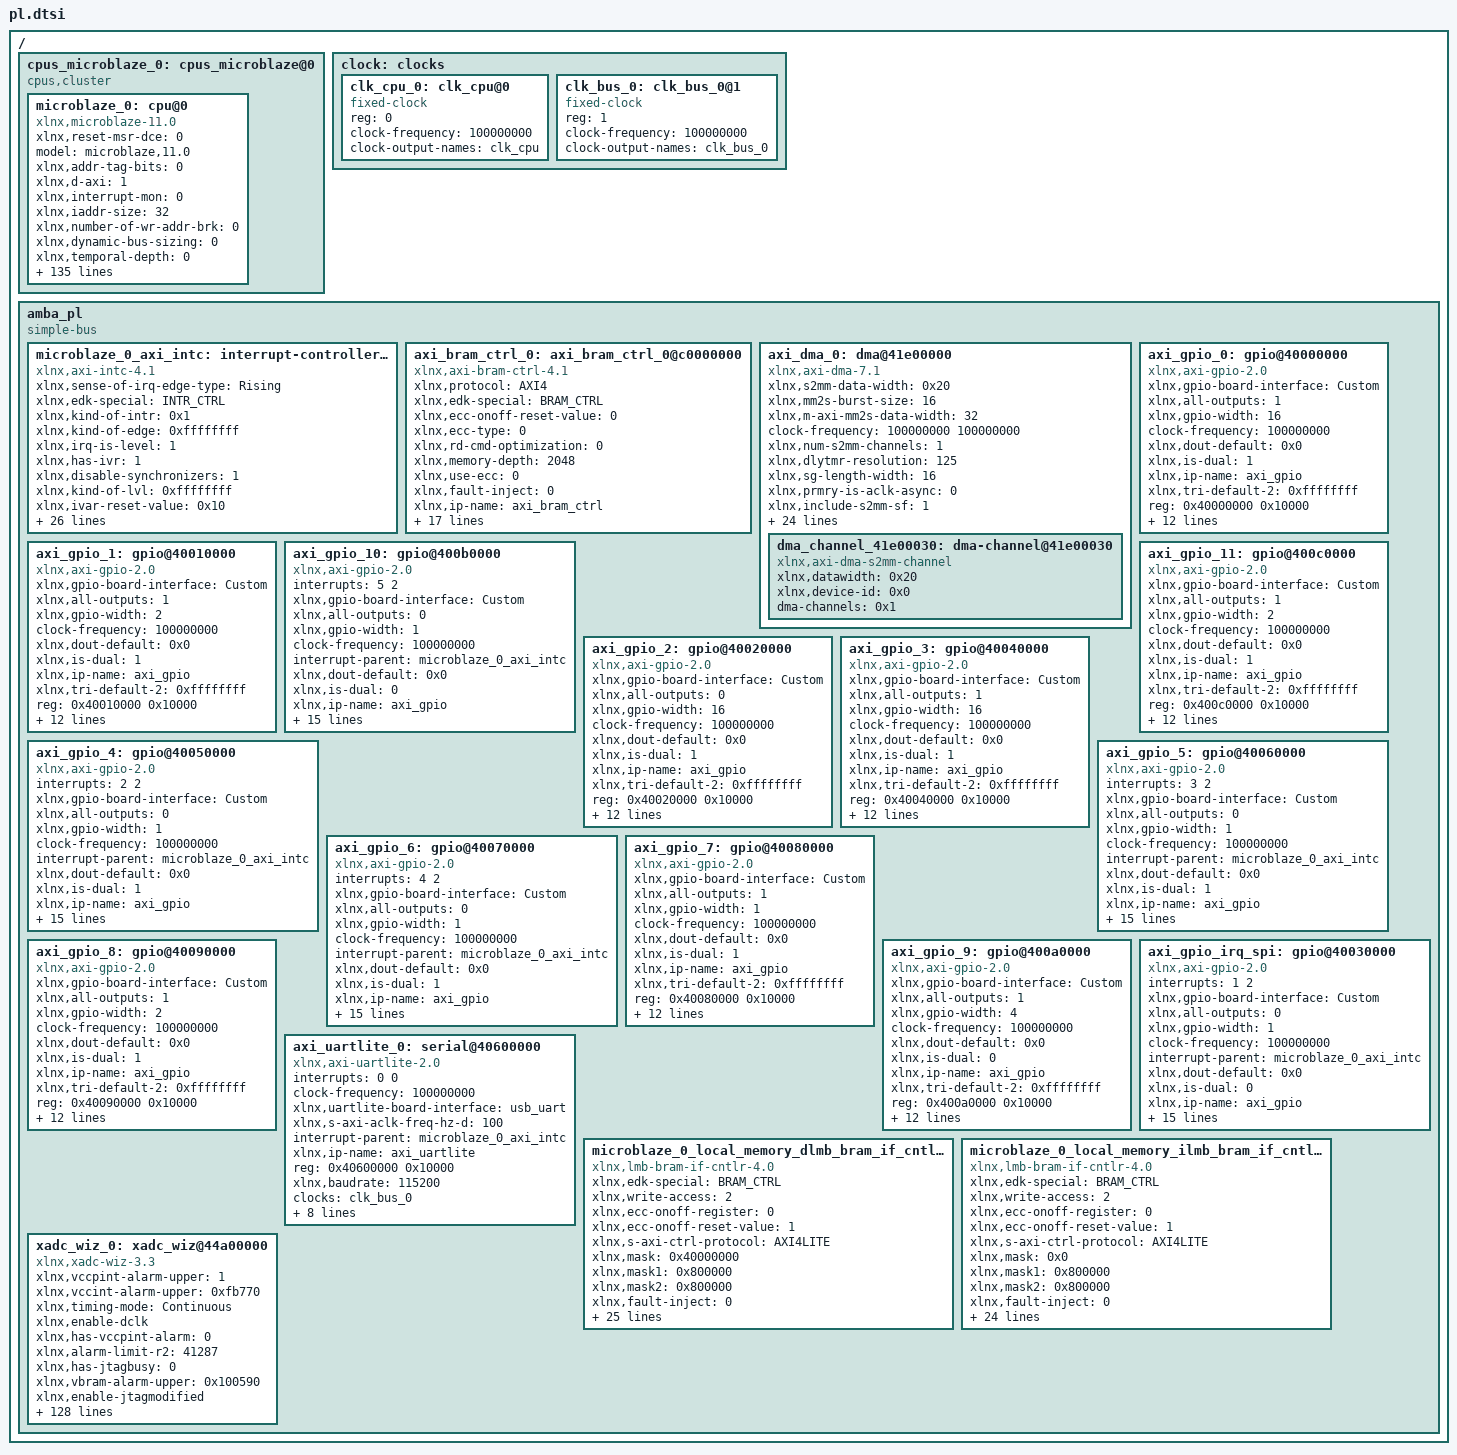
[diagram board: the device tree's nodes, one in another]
/ {
	cpus_microblaze_0: cpus_microblaze@0 {
		#cpu-mask-cells = <1>;
		compatible = "cpus,cluster";
		#address-cells = <1>;
		#size-cells = <0>;
		microblaze_0: cpu@0 {
			xlnx,reset-msr-dce = <0>;
			model = "microblaze,11.0";
			xlnx,addr-tag-bits = <0>;
			xlnx,d-axi = <1>;
			xlnx,interrupt-mon = <0>;
			xlnx,iaddr-size = <32>;
			xlnx,number-of-wr-addr-brk = <0>;
			xlnx,dynamic-bus-sizing = <0>;
			xlnx,temporal-depth = <0>;
			xlnx,use-interrupt = <2>;
			xlnx,optimization = <0>;
			xlnx,ip-axi-mon = <0>;
			xlnx,ip-name = "microblaze";
			d-cache-highaddr = <0x3fffffff>;
			xlnx,dcache-force-tag-lutram = <0>;
			xlnx,pc-width = <32>;
			xlnx,interrupt-is-edge = <0>;
			reg = <0x0>;
			xlnx,async-interrupt = <1>;
			xlnx,use-mmu = <0>;
			xlnx,reset-msr-ee = <0>;
			xlnx,icache-victims = <0>;
			xlnx,use-reorder-instr = <1>;
			xlnx,d-lmb-mon = <0>;
			xlnx,d-lmb-protocol = <0>;
			xlnx,ill-opcode-exception = <0>;
			xlnx,dcache-always-used = <1>;
			xlnx,use-div = <0>;
			xlnx,dc-axi-mon = <0>;
			xlnx,debug-trace-async-reset = <0>;
			xlnx,trace = <0>;
			xlnx,part = "xc7a35tcpg236-1";
			i-cache-baseaddr = <0x0>;
			xlnx,use-config-reset = <0>;
			xlnx,pvr = <0>;
			xlnx,i-lmb-mon = <0>;
			xlnx,dcache-byte-size = <8192>;
			xlnx,fault-tolerant = <0>;
			xlnx,family = "artix7";
			compatible = "xlnx,microblaze-11.0" , "xlnx,microblaze";
			xlnx,data-size = <32>;
			xlnx,mmu-zones = <16>;
			xlnx,debug-trace-size = <8192>;
			xlnx,mmu-privileged-instr = <0>;
			xlnx,enable-discrete-ports = <0>;
			d-cache-line-size = <16>;
			xlnx,d-lmb = <1>;
			xlnx,sco = <0>;
			xlnx,reset-msr-eip = <0>;
			xlnx,debug-interface = <0>;
			clock-frequency = <100000000>;
			xlnx,use-ext-brk = <0>;
			xlnx,daddr-size = <32>;
			xlnx,debug-enabled = <1>;
			xlnx,reset-msr-ice = <0>;
			xlnx,num-sync-ff-dbg-trace-clk = <2>;
			xlnx,i-lmb-protocol = <0>;
			xlnx,endianness = <1>;
			xlnx,fsl-exception = <0>;
			i-cache-line-size = <16>;
			xlnx,use-extended-fsl-instr = <0>;
			xlnx,reset-msr = <0x0>;
			xlnx,dp-axi-mon = <0>;
			device_type = "cpu";
			xlnx,branch-target-cache-size = <0>;
			xlnx,dcache-use-writeback = <0>;
			xlnx,div-zero-exception = <0>;
			xlnx,mmu-tlb-access = <3>;
			bus-handle = <&amba_pl>;
			xlnx,cache-byte-size = <8192>;
			xlnx,pvr-user2 = <0x0>;
			xlnx,opcode-0x0-illegal = <0>;
			xlnx,icache-line-len = <4>;
			xlnx,ecc-use-ce-exception = <0>;
			xlnx,base-vectors = <0x0>;
			xlnx,edk-special = "microblaze";
			xlnx,use-dcache = <0>;
			xlnx,use-barrel = <0>;
			xlnx,reset-msr-bip = <0>;
			xlnx,allow-dcache-wr = <1>;
			xlnx,debug-external-trace = <0>;
			xlnx,addr-size = <32>;
			xlnx,piaddr-size = <32>;
			i-cache-highaddr = <0x3fffffff>;
			xlnx,num-sync-ff-clk-debug = <2>;
			xlnx,debug-event-counters = <5>;
			xlnx,fpu-exception = <0>;
			xlnx,allow-icache-wr = <1>;
			xlnx,g-use-exceptions = <0>;
			xlnx,i-axi = <0>;
			xlnx,g-template-list = <0>;
			xlnx,icache-streams = <0>;
			xlnx,dcache-line-len = <4>;
			xlnx,num-sync-ff-clk = <2>;
			xlnx,edk-iptype = "PROCESSOR";
			xlnx,use-stack-protection = <0>;
			xlnx,use-hw-mul = <0>;
			xlnx,num-sync-ff-dbg-clk = <1>;
			xlnx,interconnect = <2>;
			xlnx,debug-latency-counters = <1>;
			i-cache-size = <8192>;
			xlnx,exceptions-in-delay-slots = <1>;
			xlnx,use-fpu = <0>;
			xlnx,reset-msr-ie = <0>;
			xlnx,edge-is-positive = <1>;
			xlnx,use-pcmp-instr = <0>;
			xlnx,use-icache = <0>;
			d-cache-size = <8192>;
			xlnx,memory-ip-list = "microblaze_0_local_memory_ilmb_bram_if_cntlr_memory" , "microblaze_0_local_memory_dlmb_bram_if_cntlr_memory";
			xlnx,async-wakeup = <3>;
			xlnx,use-non-secure = <0>;
			xlnx,dcache-addr-tag = <0>;
			xlnx,number-of-rd-addr-brk = <0>;
			d-cache-baseaddr = <0x0>;
			xlnx,area-optimized = <0>;
			xlnx,avoid-primitives = <0>;
			xlnx,lockstep-slave = <0>;
			xlnx,use-ext-nm-brk = <0>;
			xlnx,instr-size = <32>;
			interrupt-handle = <&microblaze_0_axi_intc>;
			xlnx,icache-always-used = <1>;
			xlnx,i-lmb = <1>;
			xlnx,mmu-dtlb-size = <4>;
			xlnx,lockstep-select = <0>;
			xlnx,lmb-data-size = <32>;
			xlnx,ic-axi-mon = <0>;
			xlnx,enable-conversion = <0>;
			xlnx,num-sync-ff-clk-irq = <1>;
			xlnx,fsl-links = <0>;
			timebase-frequency = <100000000>;
			xlnx,icache-force-tag-lutram = <0>;
			xlnx,dcache-data-width = <0>;
			xlnx,dcache-victims = <0>;
			xlnx,use-branch-target-cache = <0>;
			xlnx,debug-profile-size = <0>;
			xlnx,unaligned-exceptions = <0>;
			xlnx,lockstep-master = <0>;
			xlnx,freq = <100000000>;
			xlnx,number-of-pc-brk = <1>;
			xlnx,mmu-itlb-size = <2>;
			xlnx,imprecise-exceptions = <0>;
			xlnx,use-msr-instr = <0>;
			xlnx,icache-data-width = <0>;
			xlnx,debug-counter-width = <32>;
		};
	};
	clock: clocks {
		#address-cells = <1>;
		#size-cells = <0>;
		clk_cpu_0: clk_cpu@0 {
			compatible = "fixed-clock";
			reg = <0>;
			clock-frequency = <100000000>;
			clock-output-names = "clk_cpu";
			#clock-cells = <0>;
		};
		clk_bus_0: clk_bus_0@1 {
			compatible = "fixed-clock";
			reg = <1>;
			clock-frequency = <100000000>;
			clock-output-names = "clk_bus_0";
			#clock-cells = <0>;
		};
	};
	amba_pl: amba_pl {
		ranges;
		compatible = "simple-bus";
		#address-cells = <1>;
		#size-cells = <1>;
		microblaze_0_axi_intc: interrupt-controller@41200000 {
			#interrupt-cells = <2>;
			xlnx,sense-of-irq-edge-type = "Rising";
			xlnx,edk-special = "INTR_CTRL";
			xlnx,kind-of-intr = <0x1>;
			xlnx,kind-of-edge = <0xffffffff>;
			xlnx,irq-is-level = <1>;
			xlnx,has-ivr = <1>;
			compatible = "xlnx,axi-intc-4.1" , "xlnx,xps-intc-1.00.a";
			xlnx,disable-synchronizers = <1>;
			xlnx,kind-of-lvl = <0xffffffff>;
			xlnx,ivar-reset-value = <0x10>;
			xlnx,irq-active = <0x1>;
			xlnx,en-cascade-mode = <0>;
			xlnx,ip-name = "axi_intc";
			xlnx,has-ilr = <0>;
			reg = <0x41200000 0x10000>;
			xlnx,addr-width = <0x20>;
			xlnx,s-axi-aclk-freq-mhz = <100>;
			xlnx,num-sw-intr = <0>;
			xlnx,irq-connection = <0>;
			xlnx,num-intr-inputs = <0x6>;
			xlnx,has-sie = <1>;
			xlnx,enable-async = <0>;
			xlnx,has-cie = <1>;
			xlnx,num-sync-ff = <2>;
			xlnx,edk-iptype = "PERIPHERAL";
			xlnx,mb-clk-not-connected = <1>;
			xlnx,has-ipr = <1>;
			xlnx,sense-of-irq-level-type = "Active_High";
			xlnx,cascade-master = <0>;
			xlnx,processor-clk-freq-mhz = <100>;
			status = "okay";
			xlnx,is-fast = <0x1>;
			xlnx,has-fast = <1>;
			xlnx,ivar-rst-val = <0x10>;
			interrupt-controller;
			xlnx,async-intr = <0xffffffc0>;
			xlnx,name = "microblaze_0_axi_intc";
		};
		axi_bram_ctrl_0: axi_bram_ctrl_0@c0000000 {
			xlnx,protocol = "AXI4";
			xlnx,edk-special = "BRAM_CTRL";
			compatible = "xlnx,axi-bram-ctrl-4.1" , "xlnx,axi-bram-ctrl";
			xlnx,ecc-onoff-reset-value = <0>;
			xlnx,ecc-type = <0>;
			xlnx,rd-cmd-optimization = <0>;
			xlnx,memory-depth = <2048>;
			xlnx,use-ecc = <0>;
			xlnx,fault-inject = <0>;
			xlnx,ip-name = "axi_bram_ctrl";
			reg = <0xc0000000 0x2000>;
			xlnx,bmg-instance = "EXTERNAL";
			xlnx,s-axi-ctrl-addr-width = <32>;
			xlnx,read-latency = <1>;
			xlnx,id-width = <0>;
			xlnx,s-axi-supports-narrow-burst = <0>;
			xlnx,supports-narrow-burst = <0>;
			xlnx,single-port-bram = <0>;
			xlnx,ecc = <0>;
			xlnx,edk-iptype = "PERIPHERAL";
			status = "okay";
			xlnx,data-width = <32>;
			xlnx,bram-addr-width = <11>;
			xlnx,bram-inst-mode = "EXTERNAL";
			xlnx,s-axi-ctrl-data-width = <32>;
			xlnx,mem-depth = <2048>;
			xlnx,s-axi-id-width = <1>;
			xlnx,name = "axi_bram_ctrl_0";
		};
		axi_dma_0: dma@41e00000 {
			compatible = "xlnx,axi-dma-7.1" , "xlnx,axi-dma-1.00.a";
			xlnx,s2mm-data-width = <0x20>;
			xlnx,mm2s-burst-size = <16>;
			xlnx,m-axi-mm2s-data-width = <32>;
			clock-frequency = <100000000 100000000>;
			xlnx,num-s2mm-channels = <1>;
			xlnx,dlytmr-resolution = <125>;
			xlnx,sg-length-width = <16>;
			xlnx,prmry-is-aclk-async = <0>;
			xlnx,include-s2mm-sf = <1>;
			#dma-cells = <1>;
			xlnx,ip-name = "axi_dma";
			xlnx,single-interface = <0>;
			xlnx,sg-include-stscntrl-strm = <0>;
			xlnx,include-s2mm-dre = <0>;
			reg = <0x41e00000 0x10000>;
			xlnx,addr-width = <32>;
			xlnx,include-s2mm = <1>;
			clocks = <&clk_bus_0 &clk_bus_0>;
			xlnx,s-axis-s2mm-tdata-width = <32>;
			xlnx,micro-dma = <0>;
			xlnx,increase-throughput = <0>;
			xlnx,mm2s-data-width = <0x20>;
			xlnx,addrwidth = <0x20>;
			xlnx,sg-use-stsapp-length = <0>;
			xlnx,m-axis-mm2s-tdata-width = <32>;
			xlnx,edk-iptype = "PERIPHERAL";
			xlnx,s2mm-burst-size = <16>;
			xlnx,m-axi-s2mm-data-width = <32>;
			xlnx,num-mm2s-channels = <1>;
			xlnx,enable-multi-channel = <0>;
			status = "okay";
			xlnx,include-mm2s-sf = <1>;
			clock-names = "s_axi_lite_aclk" , "m_axi_sg_aclk" , "m_axi_s2mm_aclk";
			xlnx,include-mm2s = <0>;
			xlnx,include-mm2s-dre = <0>;
			xlnx,name = "axi_dma_0";
			dma_channel_41e00030: dma-channel@41e00030 {
				xlnx,datawidth = <0x20>;
				xlnx,device-id = <0x0>;
				compatible = "xlnx,axi-dma-s2mm-channel";
				dma-channels = <0x1>;
			};
		};
		axi_gpio_0: gpio@40000000 {
			xlnx,gpio-board-interface = "Custom";
			compatible = "xlnx,axi-gpio-2.0" , "xlnx,xps-gpio-1.00.a";
			xlnx,all-outputs = <1>;
			#gpio-cells = <2>;
			xlnx,gpio-width = <16>;
			clock-frequency = <100000000>;
			xlnx,dout-default = <0x0>;
			xlnx,is-dual = <1>;
			xlnx,ip-name = "axi_gpio";
			xlnx,tri-default-2 = <0xffffffff>;
			reg = <0x40000000 0x10000>;
			xlnx,all-inputs-2 = <0>;
			clocks = <&clk_bus_0>;
			xlnx,all-outputs-2 = <1>;
			gpio-controller;
			xlnx,interrupt-present = <0>;
			xlnx,gpio2-board-interface = "Custom";
			xlnx,edk-iptype = "PERIPHERAL";
			xlnx,dout-default-2 = <0x0>;
			status = "okay";
			xlnx,gpio2-width = <16>;
			clock-names = "s_axi_aclk";
			xlnx,tri-default = <0xffffffff>;
			xlnx,name = "axi_gpio_0";
			xlnx,all-inputs = <0>;
		};
		axi_gpio_1: gpio@40010000 {
			xlnx,gpio-board-interface = "Custom";
			compatible = "xlnx,axi-gpio-2.0" , "xlnx,xps-gpio-1.00.a";
			xlnx,all-outputs = <1>;
			#gpio-cells = <2>;
			xlnx,gpio-width = <2>;
			clock-frequency = <100000000>;
			xlnx,dout-default = <0x0>;
			xlnx,is-dual = <1>;
			xlnx,ip-name = "axi_gpio";
			xlnx,tri-default-2 = <0xffffffff>;
			reg = <0x40010000 0x10000>;
			xlnx,all-inputs-2 = <0>;
			clocks = <&clk_bus_0>;
			xlnx,all-outputs-2 = <1>;
			gpio-controller;
			xlnx,interrupt-present = <0>;
			xlnx,gpio2-board-interface = "Custom";
			xlnx,edk-iptype = "PERIPHERAL";
			xlnx,dout-default-2 = <0x0>;
			status = "okay";
			xlnx,gpio2-width = <2>;
			clock-names = "s_axi_aclk";
			xlnx,tri-default = <0xffffffff>;
			xlnx,name = "axi_gpio_1";
			xlnx,all-inputs = <0>;
		};
		axi_gpio_10: gpio@400b0000 {
			#interrupt-cells = <2>;
			interrupts = < 5 2 >;
			xlnx,gpio-board-interface = "Custom";
			compatible = "xlnx,axi-gpio-2.0" , "xlnx,xps-gpio-1.00.a";
			xlnx,all-outputs = <0>;
			#gpio-cells = <2>;
			xlnx,gpio-width = <1>;
			clock-frequency = <100000000>;
			interrupt-parent = <&microblaze_0_axi_intc>;
			xlnx,dout-default = <0x0>;
			xlnx,is-dual = <0>;
			xlnx,ip-name = "axi_gpio";
			xlnx,tri-default-2 = <0xffffffff>;
			reg = <0x400b0000 0x10000>;
			xlnx,all-inputs-2 = <0>;
			clocks = <&clk_bus_0>;
			xlnx,all-outputs-2 = <0>;
			gpio-controller;
			xlnx,interrupt-present = <1>;
			xlnx,gpio2-board-interface = "Custom";
			xlnx,edk-iptype = "PERIPHERAL";
			xlnx,dout-default-2 = <0x0>;
			status = "okay";
			xlnx,gpio2-width = <32>;
			clock-names = "s_axi_aclk";
			interrupt-controller;
			interrupt-names = "ip2intc_irpt";
			xlnx,tri-default = <0xffffffff>;
			xlnx,name = "axi_gpio_10";
			xlnx,all-inputs = <1>;
		};
		axi_gpio_11: gpio@400c0000 {
			xlnx,gpio-board-interface = "Custom";
			compatible = "xlnx,axi-gpio-2.0" , "xlnx,xps-gpio-1.00.a";
			xlnx,all-outputs = <1>;
			#gpio-cells = <2>;
			xlnx,gpio-width = <2>;
			clock-frequency = <100000000>;
			xlnx,dout-default = <0x0>;
			xlnx,is-dual = <1>;
			xlnx,ip-name = "axi_gpio";
			xlnx,tri-default-2 = <0xffffffff>;
			reg = <0x400c0000 0x10000>;
			xlnx,all-inputs-2 = <0>;
			clocks = <&clk_bus_0>;
			xlnx,all-outputs-2 = <1>;
			gpio-controller;
			xlnx,interrupt-present = <0>;
			xlnx,gpio2-board-interface = "Custom";
			xlnx,edk-iptype = "PERIPHERAL";
			xlnx,dout-default-2 = <0x0>;
			status = "okay";
			xlnx,gpio2-width = <2>;
			clock-names = "s_axi_aclk";
			xlnx,tri-default = <0xffffffff>;
			xlnx,name = "axi_gpio_11";
			xlnx,all-inputs = <0>;
		};
		axi_gpio_2: gpio@40020000 {
			xlnx,gpio-board-interface = "Custom";
			compatible = "xlnx,axi-gpio-2.0" , "xlnx,xps-gpio-1.00.a";
			xlnx,all-outputs = <0>;
			#gpio-cells = <2>;
			xlnx,gpio-width = <16>;
			clock-frequency = <100000000>;
			xlnx,dout-default = <0x0>;
			xlnx,is-dual = <1>;
			xlnx,ip-name = "axi_gpio";
			xlnx,tri-default-2 = <0xffffffff>;
			reg = <0x40020000 0x10000>;
			xlnx,all-inputs-2 = <0>;
			clocks = <&clk_bus_0>;
			xlnx,all-outputs-2 = <1>;
			gpio-controller;
			xlnx,interrupt-present = <0>;
			xlnx,gpio2-board-interface = "Custom";
			xlnx,edk-iptype = "PERIPHERAL";
			xlnx,dout-default-2 = <0x0>;
			status = "okay";
			xlnx,gpio2-width = <16>;
			clock-names = "s_axi_aclk";
			xlnx,tri-default = <0xffffffff>;
			xlnx,name = "axi_gpio_2";
			xlnx,all-inputs = <1>;
		};
		axi_gpio_3: gpio@40040000 {
			xlnx,gpio-board-interface = "Custom";
			compatible = "xlnx,axi-gpio-2.0" , "xlnx,xps-gpio-1.00.a";
			xlnx,all-outputs = <1>;
			#gpio-cells = <2>;
			xlnx,gpio-width = <16>;
			clock-frequency = <100000000>;
			xlnx,dout-default = <0x0>;
			xlnx,is-dual = <1>;
			xlnx,ip-name = "axi_gpio";
			xlnx,tri-default-2 = <0xffffffff>;
			reg = <0x40040000 0x10000>;
			xlnx,all-inputs-2 = <0>;
			clocks = <&clk_bus_0>;
			xlnx,all-outputs-2 = <1>;
			gpio-controller;
			xlnx,interrupt-present = <0>;
			xlnx,gpio2-board-interface = "Custom";
			xlnx,edk-iptype = "PERIPHERAL";
			xlnx,dout-default-2 = <0x0>;
			status = "okay";
			xlnx,gpio2-width = <16>;
			clock-names = "s_axi_aclk";
			xlnx,tri-default = <0xffffffff>;
			xlnx,name = "axi_gpio_3";
			xlnx,all-inputs = <0>;
		};
		axi_gpio_4: gpio@40050000 {
			#interrupt-cells = <2>;
			interrupts = < 2 2 >;
			xlnx,gpio-board-interface = "Custom";
			compatible = "xlnx,axi-gpio-2.0" , "xlnx,xps-gpio-1.00.a";
			xlnx,all-outputs = <0>;
			#gpio-cells = <2>;
			xlnx,gpio-width = <1>;
			clock-frequency = <100000000>;
			interrupt-parent = <&microblaze_0_axi_intc>;
			xlnx,dout-default = <0x0>;
			xlnx,is-dual = <1>;
			xlnx,ip-name = "axi_gpio";
			xlnx,tri-default-2 = <0xffffffff>;
			reg = <0x40050000 0x10000>;
			xlnx,all-inputs-2 = <1>;
			clocks = <&clk_bus_0>;
			xlnx,all-outputs-2 = <0>;
			gpio-controller;
			xlnx,interrupt-present = <1>;
			xlnx,gpio2-board-interface = "Custom";
			xlnx,edk-iptype = "PERIPHERAL";
			xlnx,dout-default-2 = <0x0>;
			status = "okay";
			xlnx,gpio2-width = <1>;
			clock-names = "s_axi_aclk";
			interrupt-controller;
			interrupt-names = "ip2intc_irpt";
			xlnx,tri-default = <0xffffffff>;
			xlnx,name = "axi_gpio_4";
			xlnx,all-inputs = <1>;
		};
		axi_gpio_5: gpio@40060000 {
			#interrupt-cells = <2>;
			interrupts = < 3 2 >;
			xlnx,gpio-board-interface = "Custom";
			compatible = "xlnx,axi-gpio-2.0" , "xlnx,xps-gpio-1.00.a";
			xlnx,all-outputs = <0>;
			#gpio-cells = <2>;
			xlnx,gpio-width = <1>;
			clock-frequency = <100000000>;
			interrupt-parent = <&microblaze_0_axi_intc>;
			xlnx,dout-default = <0x0>;
			xlnx,is-dual = <1>;
			xlnx,ip-name = "axi_gpio";
			xlnx,tri-default-2 = <0xffffffff>;
			reg = <0x40060000 0x10000>;
			xlnx,all-inputs-2 = <1>;
			clocks = <&clk_bus_0>;
			xlnx,all-outputs-2 = <0>;
			gpio-controller;
			xlnx,interrupt-present = <1>;
			xlnx,gpio2-board-interface = "Custom";
			xlnx,edk-iptype = "PERIPHERAL";
			xlnx,dout-default-2 = <0x0>;
			status = "okay";
			xlnx,gpio2-width = <1>;
			clock-names = "s_axi_aclk";
			interrupt-controller;
			interrupt-names = "ip2intc_irpt";
			xlnx,tri-default = <0xffffffff>;
			xlnx,name = "axi_gpio_5";
			xlnx,all-inputs = <1>;
		};
		axi_gpio_6: gpio@40070000 {
			#interrupt-cells = <2>;
			interrupts = < 4 2 >;
			xlnx,gpio-board-interface = "Custom";
			compatible = "xlnx,axi-gpio-2.0" , "xlnx,xps-gpio-1.00.a";
			xlnx,all-outputs = <0>;
			#gpio-cells = <2>;
			xlnx,gpio-width = <1>;
			clock-frequency = <100000000>;
			interrupt-parent = <&microblaze_0_axi_intc>;
			xlnx,dout-default = <0x0>;
			xlnx,is-dual = <1>;
			xlnx,ip-name = "axi_gpio";
			xlnx,tri-default-2 = <0xffffffff>;
			reg = <0x40070000 0x10000>;
			xlnx,all-inputs-2 = <1>;
			clocks = <&clk_bus_0>;
			xlnx,all-outputs-2 = <0>;
			gpio-controller;
			xlnx,interrupt-present = <1>;
			xlnx,gpio2-board-interface = "Custom";
			xlnx,edk-iptype = "PERIPHERAL";
			xlnx,dout-default-2 = <0x0>;
			status = "okay";
			xlnx,gpio2-width = <1>;
			clock-names = "s_axi_aclk";
			interrupt-controller;
			interrupt-names = "ip2intc_irpt";
			xlnx,tri-default = <0xffffffff>;
			xlnx,name = "axi_gpio_6";
			xlnx,all-inputs = <1>;
		};
		axi_gpio_7: gpio@40080000 {
			xlnx,gpio-board-interface = "Custom";
			compatible = "xlnx,axi-gpio-2.0" , "xlnx,xps-gpio-1.00.a";
			xlnx,all-outputs = <1>;
			#gpio-cells = <2>;
			xlnx,gpio-width = <1>;
			clock-frequency = <100000000>;
			xlnx,dout-default = <0x0>;
			xlnx,is-dual = <1>;
			xlnx,ip-name = "axi_gpio";
			xlnx,tri-default-2 = <0xffffffff>;
			reg = <0x40080000 0x10000>;
			xlnx,all-inputs-2 = <0>;
			clocks = <&clk_bus_0>;
			xlnx,all-outputs-2 = <1>;
			gpio-controller;
			xlnx,interrupt-present = <0>;
			xlnx,gpio2-board-interface = "Custom";
			xlnx,edk-iptype = "PERIPHERAL";
			xlnx,dout-default-2 = <0x0>;
			status = "okay";
			xlnx,gpio2-width = <3>;
			clock-names = "s_axi_aclk";
			xlnx,tri-default = <0xffffffff>;
			xlnx,name = "axi_gpio_7";
			xlnx,all-inputs = <0>;
		};
		axi_gpio_8: gpio@40090000 {
			xlnx,gpio-board-interface = "Custom";
			compatible = "xlnx,axi-gpio-2.0" , "xlnx,xps-gpio-1.00.a";
			xlnx,all-outputs = <1>;
			#gpio-cells = <2>;
			xlnx,gpio-width = <2>;
			clock-frequency = <100000000>;
			xlnx,dout-default = <0x0>;
			xlnx,is-dual = <1>;
			xlnx,ip-name = "axi_gpio";
			xlnx,tri-default-2 = <0xffffffff>;
			reg = <0x40090000 0x10000>;
			xlnx,all-inputs-2 = <0>;
			clocks = <&clk_bus_0>;
			xlnx,all-outputs-2 = <1>;
			gpio-controller;
			xlnx,interrupt-present = <0>;
			xlnx,gpio2-board-interface = "Custom";
			xlnx,edk-iptype = "PERIPHERAL";
			xlnx,dout-default-2 = <0x0>;
			status = "okay";
			xlnx,gpio2-width = <2>;
			clock-names = "s_axi_aclk";
			xlnx,tri-default = <0xffffffff>;
			xlnx,name = "axi_gpio_8";
			xlnx,all-inputs = <0>;
		};
		axi_gpio_9: gpio@400a0000 {
			xlnx,gpio-board-interface = "Custom";
			compatible = "xlnx,axi-gpio-2.0" , "xlnx,xps-gpio-1.00.a";
			xlnx,all-outputs = <1>;
			#gpio-cells = <2>;
			xlnx,gpio-width = <4>;
			clock-frequency = <100000000>;
			xlnx,dout-default = <0x0>;
			xlnx,is-dual = <0>;
			xlnx,ip-name = "axi_gpio";
			xlnx,tri-default-2 = <0xffffffff>;
			reg = <0x400a0000 0x10000>;
			xlnx,all-inputs-2 = <0>;
			clocks = <&clk_bus_0>;
			xlnx,all-outputs-2 = <0>;
			gpio-controller;
			xlnx,interrupt-present = <0>;
			xlnx,gpio2-board-interface = "Custom";
			xlnx,edk-iptype = "PERIPHERAL";
			xlnx,dout-default-2 = <0x0>;
			status = "okay";
			xlnx,gpio2-width = <32>;
			clock-names = "s_axi_aclk";
			xlnx,tri-default = <0xffffffff>;
			xlnx,name = "axi_gpio_9";
			xlnx,all-inputs = <0>;
		};
		axi_gpio_irq_spi: gpio@40030000 {
			#interrupt-cells = <2>;
			interrupts = < 1 2 >;
			xlnx,gpio-board-interface = "Custom";
			compatible = "xlnx,axi-gpio-2.0" , "xlnx,xps-gpio-1.00.a";
			xlnx,all-outputs = <0>;
			#gpio-cells = <2>;
			xlnx,gpio-width = <1>;
			clock-frequency = <100000000>;
			interrupt-parent = <&microblaze_0_axi_intc>;
			xlnx,dout-default = <0x0>;
			xlnx,is-dual = <0>;
			xlnx,ip-name = "axi_gpio";
			xlnx,tri-default-2 = <0xffffffff>;
			reg = <0x40030000 0x10000>;
			xlnx,all-inputs-2 = <0>;
			clocks = <&clk_bus_0>;
			xlnx,all-outputs-2 = <0>;
			gpio-controller;
			xlnx,interrupt-present = <1>;
			xlnx,gpio2-board-interface = "Custom";
			xlnx,edk-iptype = "PERIPHERAL";
			xlnx,dout-default-2 = <0x0>;
			status = "okay";
			xlnx,gpio2-width = <32>;
			clock-names = "s_axi_aclk";
			interrupt-controller;
			interrupt-names = "ip2intc_irpt";
			xlnx,tri-default = <0xffffffff>;
			xlnx,name = "axi_gpio_irq_spi";
			xlnx,all-inputs = <1>;
		};
		axi_uartlite_0: serial@40600000 {
			interrupts = < 0 0 >;
			compatible = "xlnx,axi-uartlite-2.0" , "xlnx,xps-uartlite-1.00.a";
			clock-frequency = <100000000>;
			xlnx,uartlite-board-interface = "usb_uart";
			xlnx,s-axi-aclk-freq-hz-d = <100>;
			interrupt-parent = <&microblaze_0_axi_intc>;
			xlnx,ip-name = "axi_uartlite";
			reg = <0x40600000 0x10000>;
			xlnx,baudrate = <115200>;
			clocks = <&clk_bus_0>;
			current-speed = <115200>;
			xlnx,use-parity = <0>;
			xlnx,edk-iptype = "PERIPHERAL";
			xlnx,odd-parity = <0>;
			status = "okay";
			xlnx,use-board-flow;
			interrupt-names = "interrupt";
			xlnx,name = "axi_uartlite_0";
			xlnx,data-bits = <8>;
			xlnx,parity = "No_Parity";
		};
		microblaze_0_local_memory_dlmb_bram_if_cntlr: lmb_bram_if_cntlr@0 {
			xlnx,edk-special = "BRAM_CTRL";
			xlnx,write-access = <2>;
			compatible = "xlnx,lmb-bram-if-cntlr-4.0" , "xlnx,axi-bram-ctrl";
			xlnx,ecc-onoff-register = <0>;
			xlnx,ecc-onoff-reset-value = <1>;
			xlnx,s-axi-ctrl-protocol = "AXI4LITE";
			xlnx,mask = <0x40000000>;
			xlnx,mask1 = <0x800000>;
			xlnx,mask2 = <0x800000>;
			xlnx,fault-inject = <0>;
			xlnx,mask3 = <0x800000>;
			xlnx,ip-name = "lmb_bram_if_cntlr";
			xlnx,arbitration = <0>;
			xlnx,num-lmb = <1>;
			xlnx,mask4 = <0x800000>;
			reg = <0x00000000 0x10000>;
			xlnx,s-axi-ctrl-addr-width = <32>;
			xlnx,mask5 = <0x800000>;
			xlnx,ecc-status-registers = <0>;
			xlnx,mask6 = <0x800000>;
			xlnx,lmb-protocol = <0>;
			xlnx,ce-counter-width = <0>;
			xlnx,mask7 = <0x800000>;
			xlnx,ecc = <0>;
			xlnx,edk-iptype = "PERIPHERAL";
			xlnx,lmb-dwidth = <32>;
			xlnx,interconnect = <0>;
			xlnx,ce-failing-registers = <0>;
			xlnx,ue-failing-registers = <0>;
			status = "okay";
			xlnx,data-width = <32>;
			xlnx,s-axi-ctrl-data-width = <32>;
			xlnx,bram-awidth = <32>;
			xlnx,lmb-awidth = <32>;
			xlnx,name = "microblaze_0_local_memory_dlmb_bram_if_cntlr";
		};
		microblaze_0_local_memory_ilmb_bram_if_cntlr: lmb_bram_if_cntlr@1 {
			xlnx,edk-special = "BRAM_CTRL";
			xlnx,write-access = <2>;
			compatible = "xlnx,lmb-bram-if-cntlr-4.0" , "xlnx,axi-bram-ctrl";
			xlnx,ecc-onoff-register = <0>;
			xlnx,ecc-onoff-reset-value = <1>;
			xlnx,s-axi-ctrl-protocol = "AXI4LITE";
			xlnx,mask = <0x0>;
			xlnx,mask1 = <0x800000>;
			xlnx,mask2 = <0x800000>;
			xlnx,fault-inject = <0>;
			xlnx,mask3 = <0x800000>;
			xlnx,ip-name = "lmb_bram_if_cntlr";
			xlnx,arbitration = <0>;
			xlnx,num-lmb = <1>;
			xlnx,mask4 = <0x800000>;
			reg = <0x00000000 0x10000>;
			xlnx,s-axi-ctrl-addr-width = <32>;
			xlnx,mask5 = <0x800000>;
			xlnx,ecc-status-registers = <0>;
			xlnx,mask6 = <0x800000>;
			xlnx,lmb-protocol = <0>;
			xlnx,ce-counter-width = <0>;
			xlnx,mask7 = <0x800000>;
			xlnx,ecc = <0>;
			xlnx,edk-iptype = "PERIPHERAL";
			xlnx,lmb-dwidth = <32>;
			xlnx,interconnect = <0>;
			xlnx,ce-failing-registers = <0>;
			xlnx,ue-failing-registers = <0>;
			status = "okay";
			xlnx,s-axi-ctrl-data-width = <32>;
			xlnx,bram-awidth = <32>;
			xlnx,lmb-awidth = <32>;
			xlnx,name = "microblaze_0_local_memory_ilmb_bram_if_cntlr";
		};
		xadc_wiz_0: xadc_wiz@44a00000 {
			xlnx,vccpint-alarm-upper = <1>;
			xlnx,vccint-alarm-upper = <0xfb770>;
			xlnx,timing-mode = "Continuous";
			xlnx,enable-dclk;
			xlnx,has-vccpint-alarm = <0>;
			xlnx,alarm-limit-r2 = <41287>;
			xlnx,has-jtagbusy = <0>;
			xlnx,vbram-alarm-upper = <0x100590>;
			xlnx,enable-jtagmodified;
			xlnx,has-vbram-alarm = <0>;
			xlnx,alarm-limit-r3 = <51763>;
			xlnx,has-axi = <1>;
			xlnx,vaux0 = <0>;
			xlnx,alarm-limit-r4 = <43322>;
			xlnx,has-busy = <1>;
			xlnx,ot-alarm;
			xlnx,enable-channel;
			xlnx,vaux1 = <0>;
			xlnx,has-vccaux-alarm = <1>;
			xlnx,alarm-limit-r5 = <21190>;
			xlnx,dclk-frequency = <100>;
			xlnx,vaux2 = <0>;
			xlnx,alarm-limit-r6 = <38229>;
			xlnx,vaux3 = <0>;
			xlnx,ip-name = "xadc_wiz";
			xlnx,alarm-limit-r7 = <44622>;
			xlnx,configuration-r0 = <276>;
			xlnx,has-drp = <0>;
			xlnx,vaux4 = <1>;
			xlnx,sim-file-rel-path = "./";
			reg = <0x44a00000 0x10000>;
			xlnx,alarm-limit-r8 = <22937>;
			xlnx,configuration-r1 = <12704>;
			xlnx,external-mux-channel = "VP_VN";
			xlnx,vccint-alarm;
			xlnx,temperature-alarm-trigger = <85>;
			xlnx,vaux5 = <0>;
			xlnx,alarm-limit-r9 = <20753>;
			xlnx,configuration-r2 = <1024>;
			xlnx,has-jtaglocked = <0>;
			xlnx,vaux6 = <0>;
			xlnx,vaux7 = <0>;
			xlnx,user-temp-alarm;
			xlnx,vaux8 = <0>;
			xlnx,vaux9 = <0>;
			xlnx,vaux10 = <0>;
			xlnx,has-vn = <1>;
			xlnx,has-vccpaux-alarm = <0>;
			xlnx,acquisition-time = <10>;
			xlnx,vaux11 = <0>;
			xlnx,has-temp-bus = <0>;
			xlnx,xadc-starup-selection = "single_channel";
			xlnx,enable-busy;
			xlnx,data-width = <32>;
			xlnx,vaux12 = <0>;
			xlnx,sim-file-sel = "Default";
			xlnx,has-vp = <1>;
			xlnx,ip-type = <0x0>;
			xlnx,temperature-alarm-ot-reset = <70>;
			xlnx,vaux13 = <0>;
			xlnx,enable-convst;
			xlnx,vaux14 = <0>;
			xlnx,vccpaux-alarm-lower = <0x1a17b0>;
			xlnx,vccaux-alarm-lower = <0x1ab3f0>;
			xlnx,vaux15 = <0>;
			compatible = "xlnx,xadc-wiz-3.3" , "xlnx,axi-xadc-1.00.a";
			xlnx,has-external-mux = <0>;
			xlnx,vccaux-alarm;
			xlnx,sampling-rate = <0x000000df 0xe0288f62>;
			xlnx,has-reset = <0>;
			xlnx,adc-conversion-rate = <1000>;
			clock-frequency = <100000000>;
			xlnx,vccddro-alarm-lower = <0x118c30>;
			xlnx,enable-calibration-averaging;
			xlnx,has-user-temp-alarm = <1>;
			xlnx,enable-axi4stream;
			xlnx,has-ot-alarm = <1>;
			xlnx,has-convst = <0>;
			xlnx,single-channel-selection = "VAUXP4_VAUXN4";
			xlnx,startup-channel-selection = "single_channel";
			xlnx,interface-selection = "Enable_AXI";
			xlnx,vccpaux-alarm-upper = <0x1b7740>;
			xlnx,vccaux-alarm-upper = <0x1cd6d0>;
			status = "okay";
			xlnx,sensor-offset-and-gain-calibration;
			xlnx,vccddro-alarm-upper = <0x1312d0>;
			xlnx,name = "xadc_wiz_0";
			xlnx,external-mux = "none";
			xlnx,enable-eoc;
			xlnx,enable-jtaglocked;
			xlnx,sim-file-name = "design";
			xlnx,temperature-alarm-reset = <60>;
			xlnx,addr-width = <32>;
			clocks = <&clk_bus_0>;
			xlnx,alarm-limit-r10 = <21845>;
			xlnx,alarm-limit-r11 = <20753>;
			xlnx,alarm-limit-r12 = <39321>;
			xlnx,edk-iptype = "PERIPHERAL";
			xlnx,alarm-limit-r13 = <37355>;
			xlnx,sequencer-mode;
			xlnx,enable-jtagbusy;
			xlnx,alarm-limit-r14 = <27306>;
			xlnx,include-intr = <1>;
			xlnx,alarm-limit-r15 = <25122>;
			xlnx,fifo-depth = <7>;
			xlnx,has-eoc = <1>;
			xlnx,temperature-alarm-ot-trigger = <125>;
			xlnx,has-channel = <1>;
			xlnx,enable-eos;
			xlnx,vccpint-alarm-lower = <0xe7ef0>;
			xlnx,vccint-alarm-lower = <0xecd10>;
			xlnx,has-dclk = <1>;
			xlnx,vbram-alarm-lower = <0xe7ef0>;
			xlnx,num-wave = <1>;
			xlnx,sequence-r0 = <256>;
			xlnx,has-jtagmodified = <0>;
			xlnx,sequence-r1 = <0>;
			xlnx,enable-drp;
			xlnx,sequence-r2 = <0>;
			xlnx,has-vccint-alarm = <1>;
			xlnx,channel-averaging = "None";
			xlnx,sequence-r3 = <0>;
			xlnx,has-axi4stream = <1>;
			xlnx,sequence-r4 = <0>;
			xlnx,sequence-r5 = <0>;
			xlnx,adc-offset-and-gain-calibration;
			xlnx,waveform-type = "CONSTANT";
			xlnx,sequence-r6 = <0>;
			xlnx,vccddro-volt = "1_2";
			xlnx,sequence-r7 = <0>;
			xlnx,has-vccddro-alarm = <0>;
			xlnx,alarm-limit-r0 = <46573>;
			xlnx,has-convstclk = <0>;
			xlnx,has-eos = <1>;
			xlnx,stimulus-freq = <1>;
			xlnx,single-channel-enable-calibration;
			xlnx,alarm-limit-r1 = <22500>;
			xlnx,component-name = "design_1_xadc_wiz_0_0";
			xlnx,external-muxaddr-enable = <0>;
		};
	};
};
